# SMS_LITE_PWRCTRL_0_SMS_LITE_TIFS_PWR_MMR_44130000h register map
Vendor: Texas Instruments
Peripheral module from a debugger description file (folder am62L).
Registers are 32-bit, read-write, reset 0x0 unless marked. A register's access mark holds for its fields unless they carry their own. Offsets are as the file gives them; lines under a group give offsets from that group; [hi:lo] are bit positions; {n}, {i} and the like mark numbered series; 'fields as' and 'values as' point back to an identical list; <NAME> marks a mode.

## SMS_LITE_TIFS_PWR_MMR
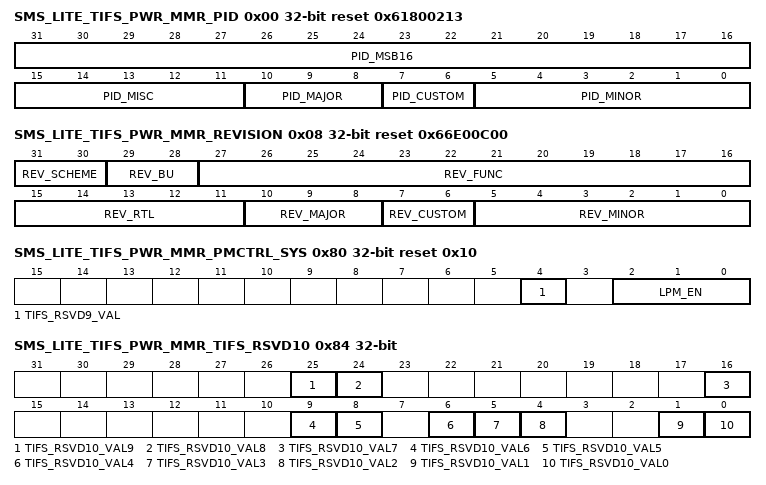
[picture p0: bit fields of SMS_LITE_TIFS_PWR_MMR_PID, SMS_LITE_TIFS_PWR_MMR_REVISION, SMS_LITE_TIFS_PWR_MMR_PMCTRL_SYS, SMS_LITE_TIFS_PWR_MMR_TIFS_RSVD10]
0x00 SMS_LITE_TIFS_PWR_MMR_PID ro reset 0x61800213
  [31:16] PID_MSB16 — Reset Source: mod_g_rst_n
  [15:11] PID_MISC — Reset Source: mod_g_rst_n
  [10:8] PID_MAJOR — Reset Source: mod_g_rst_n
  [7:6] PID_CUSTOM — Reset Source: mod_g_rst_n
  [5:0] PID_MINOR — Reset Source: mod_g_rst_n
0x08 SMS_LITE_TIFS_PWR_MMR_REVISION ro reset 0x66E00C00
  [31:30] REV_SCHEME — RTL version Reset Source: mod_por_rst_n
  [29:28] REV_BU — RTL version Reset Source: mod_por_rst_n
  [27:16] REV_FUNC — RTL version Reset Source: mod_por_rst_n
  [15:11] REV_RTL — RTL version Reset Source: mod_por_rst_n
  [10:8] REV_MAJOR — Major revision Reset Source: mod_por_rst_n
  [7:6] REV_CUSTOM — Non custom (standard) revision Reset Source: mod_por_rst_n
  [5:0] REV_MINOR — Minor revision Reset Source: mod_por_rst_n
0x20 SMS_LITE_TIFS_PWR_MMR_LOCK0_KICK0
  [31:0] LOCK0_KICK0 — - KICK0 component Reset Source: mod_g_rst_n
0x24 SMS_LITE_TIFS_PWR_MMR_LOCK0_KICK1
  [31:0] LOCK0_KICK1 — - KICK1 component Reset Source: mod_g_rst_n
0x40 SMS_LITE_TIFS_PWR_MMR_TIFS_RSVD1 ro
  [31:0] TIFS_RSVD1_VAL — Reset Source: mod_por_rst_n
0x44 SMS_LITE_TIFS_PWR_MMR_TIFS_RSVD2 access not given
  [31:0] TIFS_RSVD2_VAL — Reset Source: mod_por_rst_n (access R/W1TS)
0x48 SMS_LITE_TIFS_PWR_MMR_TIFS_RSVD3 access not given
  [31:0] TIFS_RSVD3_VAL — Reset Source: mod_por_rst_n (access R/W1TC)
0x4C SMS_LITE_TIFS_PWR_MMR_TIFS_RSVD4 ro
  [31:0] TIFS_RSVD4_VAL — Reset Source: mod_por_rst_n
0x50 SMS_LITE_TIFS_PWR_MMR_TIFS_RSVD5 ro
  [31:0] TIFS_RSVD5_VAL — Reset Source: mod_por_rst_n
0x54 SMS_LITE_TIFS_PWR_MMR_TIFS_RSVD6 access not given
  [31:0] TIFS_RSVD6_VAL — Reset Source: mod_por_rst_n (access R/W1TS)
0x58 SMS_LITE_TIFS_PWR_MMR_TIFS_RSVD7 access not given
  [31:0] TIFS_RSVD7_VAL — Reset Source: mod_por_rst_n (access R/W1TC)
0x5C SMS_LITE_TIFS_PWR_MMR_TIFS_RSVD8 ro
  [31:0] TIFS_RSVD8_VAL — Reset Source: mod_por_rst_n
0x80 SMS_LITE_TIFS_PWR_MMR_PMCTRL_SYS reset 0x10
  [4] TIFS_RSVD9_VAL — Reset Source: mod_por_rst_n
  [2:0] LPM_EN — Reset Source: mod_por_rst_n
0x84 SMS_LITE_TIFS_PWR_MMR_TIFS_RSVD10 access per field
  [25] TIFS_RSVD10_VAL9 ro — Reset Source: mod_por_rst_n
  [24] TIFS_RSVD10_VAL8 rw — Reset Source: mod_por_rst_n
  [16] TIFS_RSVD10_VAL7 rw — Reset Source: mod_por_rst_n
  [9] TIFS_RSVD10_VAL6 ro — Reset Source: mod_por_rst_n
  [8] TIFS_RSVD10_VAL5 rw — Reset Source: mod_por_rst_n
  [6] TIFS_RSVD10_VAL4 rw — Reset Source: mod_por_rst_n
  [5] TIFS_RSVD10_VAL3 ro — Reset Source: mod_por_rst_n
  [4] TIFS_RSVD10_VAL2 rw — Reset Source: mod_por_rst_n
  [1] TIFS_RSVD10_VAL1 ro — Reset Source: mod_por_rst_n
  [0] TIFS_RSVD10_VAL0 rw — Reset Source: mod_por_rst_n
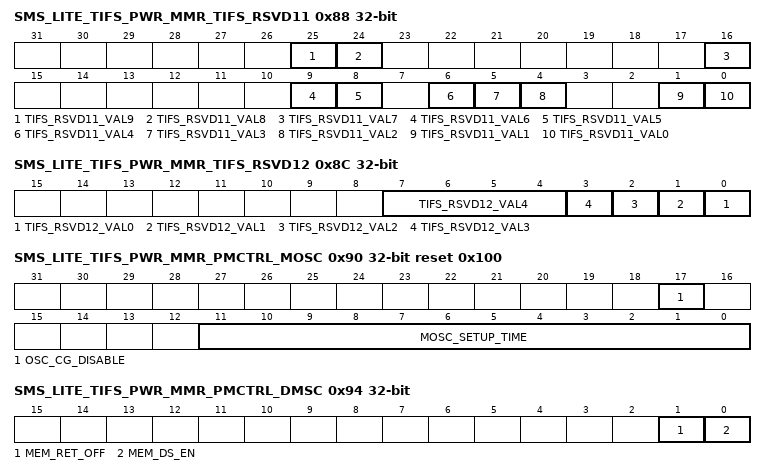
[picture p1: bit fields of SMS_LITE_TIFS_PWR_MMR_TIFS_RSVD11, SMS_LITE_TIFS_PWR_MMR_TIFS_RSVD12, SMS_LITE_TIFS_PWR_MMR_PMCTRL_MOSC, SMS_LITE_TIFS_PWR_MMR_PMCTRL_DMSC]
0x88 SMS_LITE_TIFS_PWR_MMR_TIFS_RSVD11 access per field
  [25] TIFS_RSVD11_VAL9 ro — Reset Source: mod_por_rst_n
  [24] TIFS_RSVD11_VAL8 rw — Reset Source: mod_por_rst_n
  [16] TIFS_RSVD11_VAL7 rw — Reset Source: mod_por_rst_n
  [9] TIFS_RSVD11_VAL6 ro — Reset Source: mod_por_rst_n
  [8] TIFS_RSVD11_VAL5 rw — Reset Source: mod_por_rst_n
  [6] TIFS_RSVD11_VAL4 rw — Reset Source: mod_por_rst_n
  [5] TIFS_RSVD11_VAL3 ro — Reset Source: mod_por_rst_n
  [4] TIFS_RSVD11_VAL2 rw — Reset Source: mod_por_rst_n
  [1] TIFS_RSVD11_VAL1 ro — Reset Source: mod_por_rst_n
  [0] TIFS_RSVD11_VAL0 rw — Reset Source: mod_por_rst_n
0x8C SMS_LITE_TIFS_PWR_MMR_TIFS_RSVD12
  [7:4] TIFS_RSVD12_VAL4 — Reset Source: mod_por_rst_n
  [n] TIFS_RSVD12_VAL{n} (n=0..3) — Reset Source: mod_por_rst_n
0x90 SMS_LITE_TIFS_PWR_MMR_PMCTRL_MOSC reset 0x100
  [17] OSC_CG_DISABLE — Reset Source: mod_por_rst_n
  [11:0] MOSC_SETUP_TIME — Reset Source: mod_por_rst_n
0x94 SMS_LITE_TIFS_PWR_MMR_PMCTRL_DMSC
  [1] MEM_RET_OFF — Reset Source: mod_por_rst_n
  [0] MEM_DS_EN — Reset Source: mod_por_rst_n
0x98 SMS_LITE_TIFS_PWR_MMR_PM_MISC_STATUS ro
  [1:0] OSC_CG_STAT — Reset Source: mod_por_rst_n
0x140 SMS_LITE_TIFS_PWR_MMR_CPU_STCALIB reset 0xEA60
  [23:0] CPU_STCALIB_TENMS — SysTick Calibration Value Reset Source: mod_por_rst_n
0x180 SMS_LITE_TIFS_PWR_MMR_TIFS_RSVD13
  [31:0] TIFS_RSVD13_VAL0 — Reset Source: mod_por_rst_n
0x184 SMS_LITE_TIFS_PWR_MMR_TIFS_RSVD14
  [31:0] TIFS_RSVD14_VAL0 — Reset Source: mod_por_rst_n
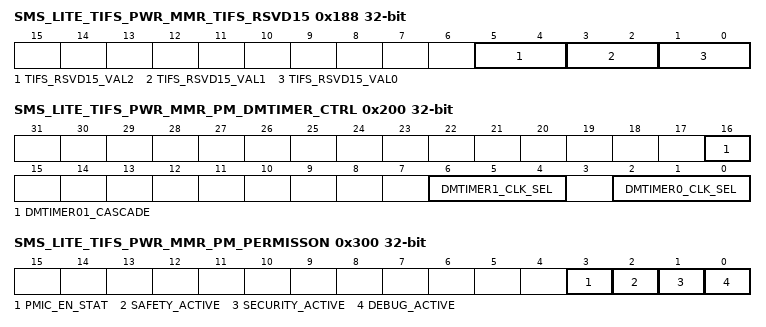
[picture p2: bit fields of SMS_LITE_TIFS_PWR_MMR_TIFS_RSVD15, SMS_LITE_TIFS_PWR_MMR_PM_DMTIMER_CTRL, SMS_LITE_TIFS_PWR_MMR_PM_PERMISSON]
0x188 SMS_LITE_TIFS_PWR_MMR_TIFS_RSVD15
  [5:4] TIFS_RSVD15_VAL2 — Reset Source: mod_por_rst_n
  [3:2] TIFS_RSVD15_VAL1 — Reset Source: mod_por_rst_n
  [1:0] TIFS_RSVD15_VAL0 — Reset Source: mod_por_rst_n
0x200 SMS_LITE_TIFS_PWR_MMR_PM_DMTIMER_CTRL
  [16] DMTIMER01_CASCADE — Reset Source: mod_por_rst_n
  [6:4] DMTIMER1_CLK_SEL — Reset Source: mod_por_rst_n
  [2:0] DMTIMER0_CLK_SEL — Reset Source: mod_por_rst_n
0x300 SMS_LITE_TIFS_PWR_MMR_PM_PERMISSON ro
  [3] PMIC_EN_STAT — Reset Source: mod_por_rst_n
  [2] SAFETY_ACTIVE — Reset Source: mod_por_rst_n
  [1] SECURITY_ACTIVE — Reset Source: mod_por_rst_n
  [0] DEBUG_ACTIVE — Reset Source: mod_por_rst_n
